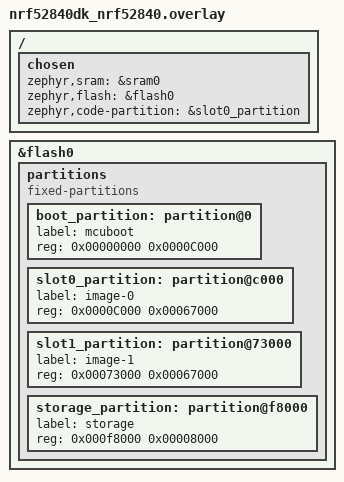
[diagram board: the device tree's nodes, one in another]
/ {
	chosen {
		zephyr,sram = &sram0;
		zephyr,flash = &flash0;
		zephyr,code-partition = &slot0_partition;
	};

};

&flash0 {
	/delete-node/ partitions;

	partitions {

		compatible = "fixed-partitions";
		#address-cells = <1>;
		#size-cells = <1>;

		boot_partition: partition@0 {
			label = "mcuboot";
			reg = <0x00000000 0x0000C000>;
		};

		slot0_partition: partition@c000 {
			label = "image-0";
			reg = <0x0000C000 0x00067000>;
		};

		slot1_partition: partition@73000 {
			label = "image-1";
			reg = <0x00073000 0x00067000>;
		};

		
		storage_partition: partition@f8000 {
			label = "storage";
			reg = <0x000f8000 0x00008000>;
		};
	};
};
